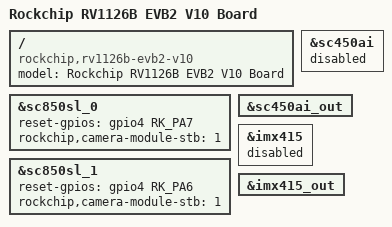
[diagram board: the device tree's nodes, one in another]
// SPDX-License-Identifier: (GPL-2.0+ OR MIT)
/*
 * Copyright (c) 2025 Rockchip Electronics Co., Ltd.
 */

/dts-v1/;
#include "rv1126b-evb2-v10.dts"
#include "rv1126b-evb-dual-cam-4k.dtsi"

/ {
	model = "Rockchip RV1126B EVB2 V10 Board";
	compatible = "rockchip,rv1126b-evb2-v10", "rockchip,rv1126b";
};

&sc850sl_0 {
	reset-gpios = <&gpio4 RK_PA7 GPIO_ACTIVE_HIGH>;
	rockchip,camera-module-stb = <1>;
};

&sc850sl_1 {
	reset-gpios = <&gpio4 RK_PA6 GPIO_ACTIVE_HIGH>;
	rockchip,camera-module-stb = <1>;
};

/* These base-board inputs are replaced by the graph above. */
&sc450ai {
	status = "disabled";
};

&sc450ai_out {
	/delete-property/ remote-endpoint;
};

&imx415 {
	status = "disabled";
};

&imx415_out {
	/delete-property/ remote-endpoint;
};
